AUTOSAR XML (schema 4-0-3)
package /ComponentTypes
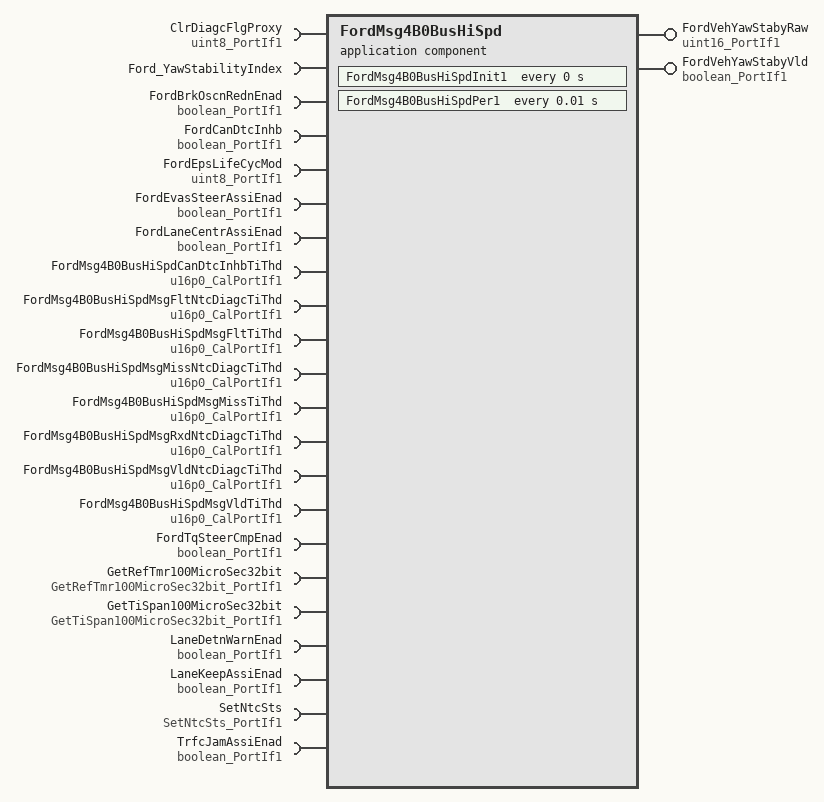
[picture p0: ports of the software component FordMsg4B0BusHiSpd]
  application sw component type FordMsg4B0BusHiSpd  # The purpose of the Ford Message 4B0 Bus High Speed function is to provide the Electric Power Steering system with signal values for the Torque Steer Compensation, Brake Oscillation Reduction, Lane Detection Warning, LKA, Traffic Jam Assist, Lane Center Assist, and Evasive Steer Assist functions from CAN. The Ford Message 4B0 function will perform the missing message and signal invalid diagnostics as well as provide a validity flag for the signal values and received message.
    provide port FordVehYawStabyRaw: nonqueued-sender-com-spec{data-element=Val, init-value=256}, provided-interface=uint16_PortIf1  # Customer datatype should be used. Datatype: Ford_YawStabilityIndex. Elements are: 510 - "Cx1FE_NoDataExists", 511 - "Cx1FF_Fault
    provide port FordVehYawStabyVld: nonqueued-sender-com-spec{data-element=Logl, init-value=0}, provided-interface=boolean_PortIf1  # This signal will be true if the message is present otherwise false
    22 x require port:
      ClrDiagcFlgProxy: nonqueued-receiver-com-spec{data-element=Val, filter=data-filter-type=ALWAYS, init-value=0}, required-interface=uint8_PortIf1  # When ClrDiagcFlgProxy is True, Diagnostic test is performed
      Ford_YawStabilityIndex: nonqueued-receiver-com-spec{data-element=Ford_YawStabilityIndex, filter=data-filter-type=ALWAYS, init-value=256}, required-interface=Ford_YawStabilityIndex  # Customer datatype should be used. Datatype: Ford_YawStabilityIndex. Elements are: 510 - "Cx1FE_NoDataExists", 511 - "Cx1FF_Fault
      FordBrkOscnRednEnad: nonqueued-receiver-com-spec{data-element=Logl, filter=data-filter-type=ALWAYS, init-value=0}, required-interface=boolean_PortIf1  # This signal should be set to 1 in order to Test Diagnostic NTC
      FordCanDtcInhb: nonqueued-receiver-com-spec{data-element=Logl, filter=data-filter-type=ALWAYS, init-value=1}, required-interface=boolean_PortIf1  # When CAN DTC Inhibit is FALSE, Diagnostic test is performed
      FordEpsLifeCycMod: nonqueued-receiver-com-spec{data-element=Val, filter=data-filter-type=ALWAYS, init-value=0}, required-interface=uint8_PortIf1  # This signal is used to decide calibration value to FAIL the NTC
      FordEvasSteerAssiEnad: nonqueued-receiver-com-spec{data-element=Logl, filter=data-filter-type=ALWAYS, init-value=0}, required-interface=boolean_PortIf1  # This signal should be set to 1 in order to Test Diagnostic NTC
      FordLaneCentrAssiEnad: nonqueued-receiver-com-spec{data-element=Logl, filter=data-filter-type=ALWAYS, init-value=0}, required-interface=boolean_PortIf1  # This signal should be set to 1 in order to Test Diagnostic NTC
      FordMsg4B0BusHiSpdCanDtcInhbTiThd: parameter-require-com-spec{init-value=2000, parameter=Val}, required-interface=u16p0_CalPortIf1  # It is the time threshold to check whether the condition that the FordCanDtcInhb is False lasts long enough
      FordMsg4B0BusHiSpdMsgFltNtcDiagcTiThd: parameter-require-com-spec{init-value=0, parameter=Val}, required-interface=u16p0_CalPortIf1  # It is the time threshold to check whether the condition that the value in the message is equal to 511 in NTC diagnostic logic lasts long enough
      FordMsg4B0BusHiSpdMsgFltTiThd: parameter-require-com-spec{init-value=0, parameter=Val}, required-interface=u16p0_CalPortIf1  # It is the time threshold to check whether the condition that the value in the message is equal to 511 lasts long enough
      FordMsg4B0BusHiSpdMsgMissNtcDiagcTiThd: parameter-require-com-spec{init-value=100, parameter=Val}, required-interface=u16p0_CalPortIf1  # It is the time threshold to check whether the condition that the message is missing in NTC diagnostic logic lasts long enough
      FordMsg4B0BusHiSpdMsgMissTiThd: parameter-require-com-spec{init-value=10, parameter=Val}, required-interface=u16p0_CalPortIf1  # It is the time threshold to check whether the condition that the message is missing lasts long enough
      FordMsg4B0BusHiSpdMsgRxdNtcDiagcTiThd: parameter-require-com-spec{init-value=0, parameter=Val}, required-interface=u16p0_CalPortIf1  # It is the time threshold to check whether the condition that the message is received lasts long enough
      FordMsg4B0BusHiSpdMsgVldNtcDiagcTiThd: parameter-require-com-spec{init-value=0, parameter=Val}, required-interface=u16p0_CalPortIf1  # It is the time threshold to check whether the condition that the value' in the message is less than 510 in NTC diagnostic lasts long enough
      FordMsg4B0BusHiSpdMsgVldTiThd: parameter-require-com-spec{init-value=5000, parameter=Val}, required-interface=u16p0_CalPortIf1  # It is the time threshold to check whether the condition that the value in the message is less than 510 lasts long enough
      FordTqSteerCmpEnad: nonqueued-receiver-com-spec{data-element=Logl, filter=data-filter-type=ALWAYS, init-value=0}, required-interface=boolean_PortIf1  # This signal should be set to 1 in order to Test Diagnostic NTC
      GetRefTmr100MicroSec32bit: client-com-spec=Oper, required-interface=GetRefTmr100MicroSec32bit_PortIf1  # It captures simulation time fromthe SimnTi value obtained at root laye'r of model and gives the RefTmr
      GetTiSpan100MicroSec32bit: client-com-spec=Oper, required-interface=GetTiSpan100MicroSec32bit_PortIf1  # It Captures simulation time fromSimnTi value, handles counter wrapping, and subtracts RefTmr,provides the TiSpan
      LaneDetnWarnEnad: nonqueued-receiver-com-spec{data-element=Logl, filter=data-filter-type=ALWAYS, init-value=0}, required-interface=boolean_PortIf1  # This signal should be set to 1 in order to Test Diagnostic NTC
      LaneKeepAssiEnad: nonqueued-receiver-com-spec{data-element=Logl, filter=data-filter-type=ALWAYS, init-value=0}, required-interface=boolean_PortIf1  # This signal should be set to 1 in order to Test Diagnostic NTC
      SetNtcSts: client-com-spec=Oper, required-interface=SetNtcSts_PortIf1  # Provides the Parameter byte information
      TrfcJamAssiEnad: nonqueued-receiver-com-spec{data-element=Logl, filter=data-filter-type=ALWAYS, init-value=0}, required-interface=boolean_PortIf1  # This signal should be set to 1 in order to Test Diagnostic NTC
    behavior FordMsg4B0BusHiSpd_InternalBehavior
      ar-typed-per-instance-memorys:
        15 x data, all with sw-calibration-access=READ-ONLY:
          CanDtcInhbRefTi: type=uint32  # Timer for invalid message will increment or reset based on the conditions
          ClrDiagcFlgProxyPrev: type=uint8  # It stores the previous value of ClrDiagcFlgProxy
          FordMsg4B0Miss: type=boolean  # It is used to indicate that the service ComTimeoutNotification_YawStabilityIndex is called and the message is missing
          FordVehYawStabyRawPrev: type=uint16  # Hold the Previous value of Ford Vehicle Yaw Stability Raw Previous
          FordVehYawStabyVldPrev: type=boolean  # Hold the Previous value of Ford Vehicle Yaw Stability Valid
          IniVehYawStabyInvld: type=boolean  # It is used to set FordVehYawStabyVld to True for the first time without time delay. It is set to False after FordVehYawStabyVld is set to False for the first time. Therefore, setting FordVehYawStabyVld to True has a time delay after the first time
          MsgFltNtcDiagcRefTi: type=uint32  # It is used as the reference time to calculate the elapsed time in NTC diagnostic during which the value in the message is equal to 511
          MsgFltRefTi: type=uint32  # It is used as the reference time to calculate the elapsed time during 'which the value in the message is equal to 511
          MsgMissNtcDiagcRefTi: type=uint32  # 'It is used as the reference time to calculate the elapsed time in NTC diagnostic during which the message is missing.'
          MsgNoDataExistNtcDiagcRefTi: type=uint32  # It is used as the reference time to calculate the elapsed time in NTC diagnostic during which the value in the message is equal to 510
          MsgNoDataExistRefTi: type=uint32  # It is used as the reference time to calculate the elapsed time during which the value in the message is equal to 510
          MsgNotRxdRefTi: type=uint32  # It is used as the reference time to calculate the elapsed time durig which the message is not received
          MsgRxdNtcDiagcRefTi: type=uint32  # It is used as the reference time to calculate the elapsed time in NTC diagnostic during which the message is received
          MsgVldNtcDiagcRefTi: type=uint32  # It is used as the reference time to calculate the elapsed time in NTC diagnostic during which the value in the message is less than 510
          MsgVldRefTi: type=uint32  # It is used as the reference time to calculate the elapsed time during which the value in the message is less than 510
      timing event FordMsg4B0BusHiSpd_InitEvent: start-on-event=FordMsg4B0BusHiSpdInit1, period=0
      timing event TMT_FordMsg4B0BusHiSpdPer1: start-on-event=FordMsg4B0BusHiSpdPer1, period=0.01
      port-api-options:
        enable-take-address=false, indirect-api=false, port=ClrDiagcFlgProxy
        enable-take-address=false, indirect-api=false, port=Ford_YawStabilityIndex
        enable-take-address=false, indirect-api=false, port=FordBrkOscnRednEnad
        enable-take-address=false, indirect-api=false, port=FordCanDtcInhb
        enable-take-address=false, indirect-api=false, port=FordEpsLifeCycMod
        enable-take-address=false, indirect-api=false, port=FordEvasSteerAssiEnad
        enable-take-address=false, indirect-api=false, port=FordLaneCentrAssiEnad
        enable-take-address=false, indirect-api=false, port=FordMsg4B0BusHiSpdCanDtcInhbTiThd
        enable-take-address=false, indirect-api=false, port=FordMsg4B0BusHiSpdMsgFltNtcDiagcTiThd
        enable-take-address=false, indirect-api=false, port=FordMsg4B0BusHiSpdMsgFltTiThd
        enable-take-address=false, indirect-api=false, port=FordMsg4B0BusHiSpdMsgMissNtcDiagcTiThd
        enable-take-address=false, indirect-api=false, port=FordMsg4B0BusHiSpdMsgMissTiThd
        enable-take-address=false, indirect-api=false, port=FordMsg4B0BusHiSpdMsgRxdNtcDiagcTiThd
        enable-take-address=false, indirect-api=false, port=FordMsg4B0BusHiSpdMsgVldNtcDiagcTiThd
        enable-take-address=false, indirect-api=false, port=FordMsg4B0BusHiSpdMsgVldTiThd
        enable-take-address=false, indirect-api=false, port=FordTqSteerCmpEnad
        enable-take-address=false, indirect-api=false, port=FordVehYawStabyRaw
        enable-take-address=false, indirect-api=false, port=FordVehYawStabyVld
        enable-take-address=false, indirect-api=false, port=GetRefTmr100MicroSec32bit
        enable-take-address=false, indirect-api=false, port=GetTiSpan100MicroSec32bit
        enable-take-address=false, indirect-api=false, port=LaneDetnWarnEnad
        enable-take-address=false, indirect-api=false, port=LaneKeepAssiEnad
        enable-take-address=false, indirect-api=false, port=SetNtcSts
        enable-take-address=false, indirect-api=false, port=TrfcJamAssiEnad
      runnable FordMsg4B0BusHiSpdInit1: minimum-start-interval=0.01  # Initialization Runnable
        sync call SC_GetRefTmr100MicroSec32bit_Oper: operation=GetRefTmr100MicroSec32bit.Oper, timeout=0
      runnable FordMsg4B0BusHiSpdPer1: minimum-start-interval=0.01  # Periodic Runnable at 10 millisecond
        data-receive-point-by-arguments:
          11 x access:
            REC_ClrDiagcFlgProxy_Val: accessed-variable=ClrDiagcFlgProxy.Val
            REC_Ford_YawStabilityIndex_Ford_YawStabilityIndex: accessed-variable=Ford_YawStabilityIndex.Ford_YawStabilityIndex
            REC_FordBrkOscnRednEnad_Logl: accessed-variable=FordBrkOscnRednEnad.Logl
            REC_FordCanDtcInhb_Logl: accessed-variable=FordCanDtcInhb.Logl
            REC_FordEpsLifeCycMod_Val: accessed-variable=FordEpsLifeCycMod.Val
            REC_FordEvasSteerAssiEnad_Logl: accessed-variable=FordEvasSteerAssiEnad.Logl
            REC_FordLaneCentrAssiEnad_Logl: accessed-variable=FordLaneCentrAssiEnad.Logl
            REC_FordTqSteerCmpEnad_Logl: accessed-variable=FordTqSteerCmpEnad.Logl
            REC_LaneDetnWarnEnad_Logl: accessed-variable=LaneDetnWarnEnad.Logl
            REC_LaneKeepAssiEnad_Logl: accessed-variable=LaneKeepAssiEnad.Logl
            REC_TrfcJamAssiEnad_Logl: accessed-variable=TrfcJamAssiEnad.Logl
        data-send-points:
          access SEND_FordVehYawStabyRaw_Val: accessed-variable=FordVehYawStabyRaw.Val
          access SEND_FordVehYawStabyVld_Logl: accessed-variable=FordVehYawStabyVld.Logl
        sync call SC_GetRefTmr100MicroSec32bit_Oper: operation=GetRefTmr100MicroSec32bit.Oper, timeout=0
        sync call SC_GetTiSpan100MicroSec32bit_Oper: operation=GetTiSpan100MicroSec32bit.Oper, timeout=0
        sync call SC_SetNtcSts_Oper: operation=SetNtcSts.Oper, timeout=0
  swc implementation FordMsg4B0BusHiSpd_Implementation: behavior=FordMsg4B0BusHiSpd_InternalBehavior
    code-descriptors:
      code Default: artifact-descriptors=autosar-engineering-object={short-label=Default, category=SWSRC}
